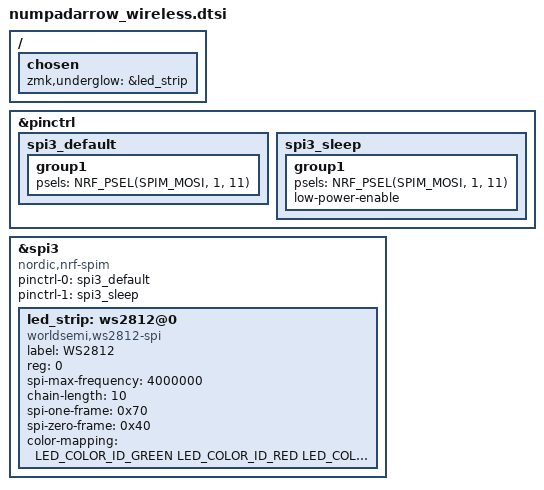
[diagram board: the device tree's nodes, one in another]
/*
 * Copyright (c) 2020 Pete Johanson, Richard Jones
 *
 * SPDX-License-Identifier: MIT
 */

#include <dt-bindings/zmk/matrix_transform.h>
#include <dt-bindings/led/led.h>

/ {
    chosen {
        //zmk,kscan = &kscan0;
        zmk,underglow = &led_strip;
    };

/*
    kscan0: kscan {
        compatible = "zmk,kscan-gpio-matrix";
        label = "KSCAN";

        diode-direction = "col2row";
        row-gpios
            = <&pro_micro 4 (GPIO_ACTIVE_HIGH | GPIO_PULL_DOWN)>
            , <&pro_micro 5 (GPIO_ACTIVE_HIGH | GPIO_PULL_DOWN)>
            , <&pro_micro 6 (GPIO_ACTIVE_HIGH | GPIO_PULL_DOWN)>
            , <&pro_micro 7 (GPIO_ACTIVE_HIGH | GPIO_PULL_DOWN)>
            ;

        col-gpios
            = <&pro_micro 18 GPIO_ACTIVE_HIGH>
            , <&pro_micro 15 GPIO_ACTIVE_HIGH>
            , <&pro_micro 14 GPIO_ACTIVE_HIGH>
            ;

    };

    */
};

&pinctrl {
    spi3_default: spi3_default {
        group1 {
            psels = <NRF_PSEL(SPIM_MOSI, 1, 11)>;
        };
    };

    spi3_sleep: spi3_sleep {
        group1 {
            psels = <NRF_PSEL(SPIM_MOSI, 1, 11)>;
            low-power-enable;
        };
    };
};

&spi3 {
  compatible = "nordic,nrf-spim";
  status = "okay";

  pinctrl-0 = <&spi3_default>;
  pinctrl-1 = <&spi3_sleep>;
  pinctrl-names = "default", "sleep";

  led_strip: ws2812@0 {
    compatible = "worldsemi,ws2812-spi";
    label = "WS2812";

    /* SPI */
    reg = <0>; /* ignored, but necessary for SPI bindings */
    spi-max-frequency = <4000000>;

    /* WS2812 */
    chain-length = <10>; /* number of LEDs */
    spi-one-frame = <0x70>;
    spi-zero-frame = <0x40>;
    color-mapping = <LED_COLOR_ID_GREEN
                          LED_COLOR_ID_RED
                          LED_COLOR_ID_BLUE>;
  };
};
